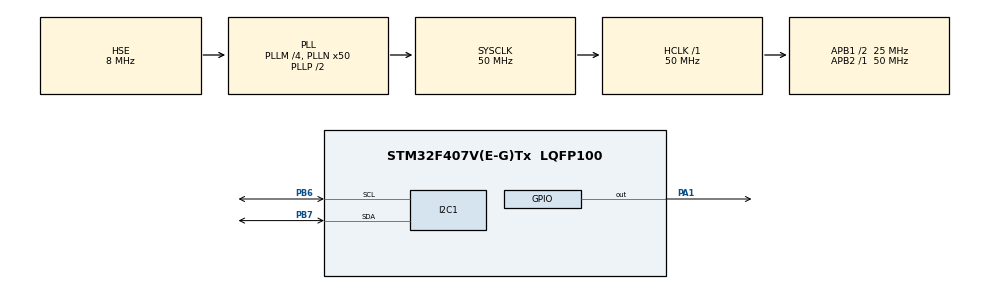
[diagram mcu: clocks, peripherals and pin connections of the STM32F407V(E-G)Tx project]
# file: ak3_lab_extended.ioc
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Mcu.Family=STM32F4
Mcu.Name=STM32F407V(E-G)Tx
Mcu.Package=LQFP100
NVIC.PriorityGroup=NVIC_PRIORITYGROUP_4
PA1.Signal=GPIO_Output
PB6.Mode=I2C
PB6.Signal=I2C1_SCL
PB7.Mode=I2C
PB7.Signal=I2C1_SDA
PH0-OSC_IN.Mode=HSE-External-Oscillator
PH0-OSC_IN.Signal=RCC_OSC_IN
PH1-OSC_OUT.Mode=HSE-External-Oscillator
PH1-OSC_OUT.Signal=RCC_OSC_OUT
ProjectManager.HeapSize=0x200
ProjectManager.StackSize=0x400
ProjectManager.TargetToolchain=STM32CubeIDE
RCC.48MHZClocksFreq_Value=25000000
RCC.AHBFreq_Value=50000000
RCC.APB1CLKDivider=RCC_HCLK_DIV2
RCC.APB1Freq_Value=25000000
RCC.APB1TimFreq_Value=50000000
RCC.APB2Freq_Value=50000000
RCC.APB2TimFreq_Value=50000000
RCC.CortexFreq_Value=50000000
RCC.HCLKFreq_Value=50000000
RCC.HSE_VALUE=8000000
RCC.HSI_VALUE=16000000
RCC.LSE_VALUE=32768
RCC.PLLM=4
RCC.PLLN=50
RCC.PLLSourceVirtual=RCC_PLLSOURCE_HSE
RCC.SYSCLKFreq_VALUE=50000000
RCC.SYSCLKSource=RCC_SYSCLKSOURCE_PLLCLK
RCC.VCOOutputFreq_Value=100000000
TIM6.Period=0xffff-1
TIM6.Prescaler=50-1
VP_TIM6_VS_ClockSourceINT.Mode=Enable_Timer
board=custom

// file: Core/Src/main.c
/* USER CODE BEGIN Header */
/**
  ******************************************************************************
  * @file           : main.c
  * @brief          : Main program body
  ******************************************************************************
  * @attention
  *
  * Copyright (c) 2024 STMicroelectronics.
  * All rights reserved.
  *
  * This software is licensed under terms that can be found in the LICENSE file
  * in the root directory of this software component.
  * If no LICENSE file comes with this software, it is provided AS-IS.
  *
  ******************************************************************************
  */
/* USER CODE END Header */
#include "main.h"

/* USER CODE BEGIN Includes */
#include "lcd_display_driver.h"

/* USER CODE END Includes */

I2C_HandleTypeDef hi2c1;

TIM_HandleTypeDef htim6;

void SystemClock_Config(void);
static void MX_GPIO_Init(void);
static void MX_I2C1_Init(void);
static void MX_TIM6_Init(void);

/* USER CODE BEGIN 0 */
#define DHT11_PORT GPIOA
#define DHT11_PIN GPIO_PIN_1

float Temperature = 0;
float Humidity = 0;
uint8_t Check = 0;
uint8_t Hm_byte1, Hm_byte2;
uint8_t Temp_byte1, Temp_byte2;
uint16_t SUM;

void Set_Pin_Output(GPIO_TypeDef *GPIOx, uint16_t GPIO_Pin)
{
	GPIO_InitTypeDef GPIO_InitStruct = {0};
	GPIO_InitStruct.Pin = GPIO_Pin;
	GPIO_InitStruct.Mode = GPIO_MODE_OUTPUT_PP;
	GPIO_InitStruct.Speed = GPIO_SPEED_FREQ_LOW;
	HAL_GPIO_Init(GPIOx, &GPIO_InitStruct);
}

void Set_Pin_Input(GPIO_TypeDef *GPIOx, uint16_t GPIO_Pin)
{
	GPIO_InitTypeDef GPIO_InitStruct = {0};
	GPIO_InitStruct.Pin = GPIO_Pin;
	GPIO_InitStruct.Mode = GPIO_MODE_INPUT;
	GPIO_InitStruct.Pull = GPIO_PULLUP;
	HAL_GPIO_Init(GPIOx, &GPIO_InitStruct);
}

void delay(uint16_t time)
{
	__HAL_TIM_SET_COUNTER(&htim6, 0);
	while((__HAL_TIM_GET_COUNTER(&htim6))<time);
}

void dht11_init(void)
{
	Set_Pin_Output(DHT11_PORT, DHT11_PIN);
	HAL_GPIO_WritePin(DHT11_PORT, DHT11_PIN, 0);
	delay(18000);
	HAL_GPIO_WritePin(DHT11_PORT, DHT11_PIN, 1);
	delay(20);
	Set_Pin_Input(DHT11_PORT, DHT11_PIN);
}

uint8_t dht11_checkResponse(void)
{
	uint8_t res = 0;
	delay(40);
	if(!(HAL_GPIO_ReadPin(DHT11_PORT, DHT11_PIN)))
	{
		delay(80);
		if((HAL_GPIO_ReadPin(DHT11_PORT, DHT11_PIN)))
		{
			res = 1;
		}
		else
		{
			res = -1;
		}
	}
	while((HAL_GPIO_ReadPin (DHT11_PORT, DHT11_PIN)));

	return res;
}

uint8_t dht11_readData(void)
{
	uint8_t i,j;
	for(j=0; j<8; j++)
	{
		while(!(HAL_GPIO_ReadPin (DHT11_PORT, DHT11_PIN)));
		delay(40);
		if(!(HAL_GPIO_ReadPin (DHT11_PORT, DHT11_PIN)))
		{
			i&= ~(1<<(7-j));
		}
		else i|= (1<<(7-j));

		while((HAL_GPIO_ReadPin (DHT11_PORT, DHT11_PIN)));
	}

	return i;
}

/* USER CODE END 0 */

int main(void)
{

  /* MCU Configuration--------------------------------------------------------*/

  /* Reset of all peripherals, Initializes the Flash interface and the Systick. */
  HAL_Init();

  /* Configure the system clock */
  SystemClock_Config();

  /* Initialize all configured peripherals */
  MX_GPIO_Init();
  MX_I2C1_Init();
  MX_TIM6_Init();
  /* USER CODE BEGIN 2 */
  HAL_TIM_Base_Start(&htim6);

  if(display_init(&hi2c1))
  {
	  HAL_GPIO_WritePin(GPIOD, GPIO_PIN_12, GPIO_PIN_SET);
  }
  display_setCursor(0, 0);
  display_printf("Initializing...");
  HAL_Delay(3000);
  display_clear();
  /* USER CODE END 2 */

  /* Infinite loop */
  while (1)
  {
	  dht11_init();
	  Check = dht11_checkResponse();
	  Hm_byte1 = dht11_readData();
	  Hm_byte2 = dht11_readData();
	  Temp_byte1 = dht11_readData();
	  Temp_byte2 = dht11_readData();
	  SUM = dht11_readData();

	  Temperature = (float) Temp_byte1;
	  Humidity = (float) Hm_byte1;

	  display_setCursor(0, 0);
	  display_printf("TEMP: %.2f C", Temperature);
	  display_setCursor(0, 1);
	  display_printf("HM:   %.2f ", Humidity);
	  display_printf("%%");

	  HAL_Delay(3000);
  }
}

void SystemClock_Config(void)
{
  RCC_OscInitTypeDef RCC_OscInitStruct = {0};
  RCC_ClkInitTypeDef RCC_ClkInitStruct = {0};

  /** Configure the main internal regulator output voltage
  */
  __HAL_RCC_PWR_CLK_ENABLE();
  __HAL_PWR_VOLTAGESCALING_CONFIG(PWR_REGULATOR_VOLTAGE_SCALE1);

  /** Initializes the RCC Oscillators according to the specified parameters
  * in the RCC_OscInitTypeDef structure.
  */
  RCC_OscInitStruct.OscillatorType = RCC_OSCILLATORTYPE_HSE;
  RCC_OscInitStruct.HSEState = RCC_HSE_ON;
  RCC_OscInitStruct.PLL.PLLState = RCC_PLL_ON;
  RCC_OscInitStruct.PLL.PLLSource = RCC_PLLSOURCE_HSE;
  RCC_OscInitStruct.PLL.PLLM = 4;
  RCC_OscInitStruct.PLL.PLLN = 50;
  RCC_OscInitStruct.PLL.PLLP = RCC_PLLP_DIV2;
  RCC_OscInitStruct.PLL.PLLQ = 4;
  if (HAL_RCC_OscConfig(&RCC_OscInitStruct) != HAL_OK)
  {
    Error_Handler();
  }

  /** Initializes the CPU, AHB and APB buses clocks
  */
  RCC_ClkInitStruct.ClockType = RCC_CLOCKTYPE_HCLK|RCC_CLOCKTYPE_SYSCLK
                              |RCC_CLOCKTYPE_PCLK1|RCC_CLOCKTYPE_PCLK2;
  RCC_ClkInitStruct.SYSCLKSource = RCC_SYSCLKSOURCE_PLLCLK;
  RCC_ClkInitStruct.AHBCLKDivider = RCC_SYSCLK_DIV1;
  RCC_ClkInitStruct.APB1CLKDivider = RCC_HCLK_DIV2;
  RCC_ClkInitStruct.APB2CLKDivider = RCC_HCLK_DIV1;

  if (HAL_RCC_ClockConfig(&RCC_ClkInitStruct, FLASH_LATENCY_1) != HAL_OK)
  {
    Error_Handler();
  }
}

static void MX_I2C1_Init(void)
{

  hi2c1.Instance = I2C1;
  hi2c1.Init.ClockSpeed = 100000;
  hi2c1.Init.DutyCycle = I2C_DUTYCYCLE_2;
  hi2c1.Init.OwnAddress1 = 0;
  hi2c1.Init.AddressingMode = I2C_ADDRESSINGMODE_7BIT;
  hi2c1.Init.DualAddressMode = I2C_DUALADDRESS_DISABLE;
  hi2c1.Init.OwnAddress2 = 0;
  hi2c1.Init.GeneralCallMode = I2C_GENERALCALL_DISABLE;
  hi2c1.Init.NoStretchMode = I2C_NOSTRETCH_DISABLE;
  if (HAL_I2C_Init(&hi2c1) != HAL_OK)
  {
    Error_Handler();
  }

}

static void MX_TIM6_Init(void)
{

  TIM_MasterConfigTypeDef sMasterConfig = {0};

  htim6.Instance = TIM6;
  htim6.Init.Prescaler = 50-1;
  htim6.Init.CounterMode = TIM_COUNTERMODE_UP;
  htim6.Init.Period = 0xffff-1;
  htim6.Init.AutoReloadPreload = TIM_AUTORELOAD_PRELOAD_DISABLE;
  if (HAL_TIM_Base_Init(&htim6) != HAL_OK)
  {
    Error_Handler();
  }
  sMasterConfig.MasterOutputTrigger = TIM_TRGO_RESET;
  sMasterConfig.MasterSlaveMode = TIM_MASTERSLAVEMODE_DISABLE;
  if (HAL_TIMEx_MasterConfigSynchronization(&htim6, &sMasterConfig) != HAL_OK)
  {
    Error_Handler();
  }

}

static void MX_GPIO_Init(void)
{
  GPIO_InitTypeDef GPIO_InitStruct = {0};

  /* GPIO Ports Clock Enable */
  __HAL_RCC_GPIOH_CLK_ENABLE();
  __HAL_RCC_GPIOA_CLK_ENABLE();
  __HAL_RCC_GPIOB_CLK_ENABLE();

  /*Configure GPIO pin Output Level */
  HAL_GPIO_WritePin(GPIOA, GPIO_PIN_1, GPIO_PIN_RESET);

  /*Configure GPIO pin : PA1 */
  GPIO_InitStruct.Pin = GPIO_PIN_1;
  GPIO_InitStruct.Mode = GPIO_MODE_OUTPUT_PP;
  GPIO_InitStruct.Pull = GPIO_NOPULL;
  GPIO_InitStruct.Speed = GPIO_SPEED_FREQ_LOW;
  HAL_GPIO_Init(GPIOA, &GPIO_InitStruct);

}

void Error_Handler(void)
{
  __disable_irq();
  while (1)
  {
  }
}
